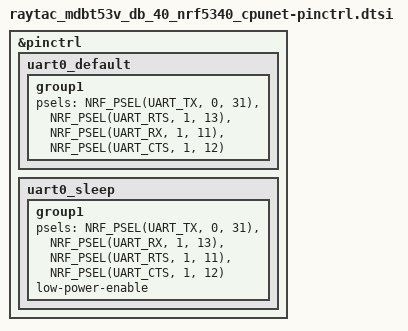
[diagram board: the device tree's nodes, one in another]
/*
 * Copyright (c) 2023 Raytac Corporation
 *
 * SPDX-License-Identifier: Apache-2.0
 */

&pinctrl {
	uart0_default: uart0_default {
		group1 {
			psels = <NRF_PSEL(UART_TX, 0, 31)>,
				<NRF_PSEL(UART_RTS, 1, 13)>,
			    <NRF_PSEL(UART_RX, 1, 11)>,
				<NRF_PSEL(UART_CTS, 1, 12)>;
		};
	};

	uart0_sleep: uart0_sleep {
		group1 {
			psels = <NRF_PSEL(UART_TX, 0, 31)>,
				<NRF_PSEL(UART_RX, 1, 13)>,
				<NRF_PSEL(UART_RTS, 1, 11)>,
				<NRF_PSEL(UART_CTS, 1, 12)>;
			low-power-enable;
		};
	};

};
